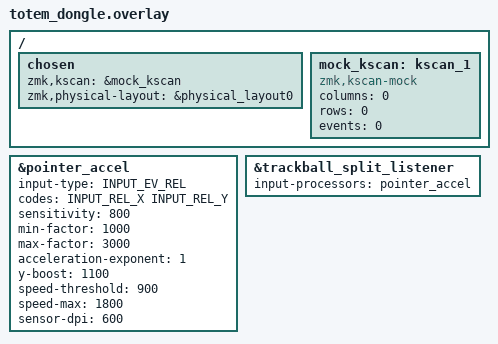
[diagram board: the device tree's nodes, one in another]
#include "totem.dtsi"
#include <input/processors.dtsi>
#include "input-split.dtsi"
#include "totem-layouts.dtsi"
#include <behaviors/input_gestures_accel.dtsi>

&pointer_accel { // this needs to be put BEFORE input-listener
    input-type = <INPUT_EV_REL>;
    codes = <INPUT_REL_X INPUT_REL_Y>;
    sensitivity = <800>;         // 0.8x base sensitivity
	min-factor = <800>;			  // 0.8x minimum for percision
    max-factor = <3000>;          // 3.0x maximum acceleration
    acceleration-exponent = <1>;  // Advanced exponential curve (1-5)
    y-boost = <1100>;             // 1.1x Y-axis boost for widescreen
    speed-threshold = <900>;      // Start acceleration at 900 counts/sec, just 1.5 inch/sec
    speed-max = <1800>;           // Max acceleration at 1800 counts/sec, just 3 inch/sec
    min-factor = <1000>;          // 1.0x minimum (no deceleration)
	sensor-dpi = <600>;
};

&trackball_split_listener {
	status = "okay";
	input-processors = <&pointer_accel>;
};

// &kscan0 {
//     col-gpios
//         = <&xiao_d 4 GPIO_ACTIVE_HIGH>
//         , <&xiao_d 5 GPIO_ACTIVE_HIGH>
//         , <&xiao_d 10 GPIO_ACTIVE_HIGH>
//         , <&xiao_d 9 GPIO_ACTIVE_HIGH>
//         , <&xiao_d 8 GPIO_ACTIVE_HIGH>
//         ;
// };

/ {
    chosen {
        zmk,kscan = &mock_kscan;
        zmk,physical-layout = &physical_layout0;
    };

    mock_kscan: kscan_1 {
        compatible = "zmk,kscan-mock";
        columns = <0>;
        rows = <0>;
        events = <0>;
    };
};
